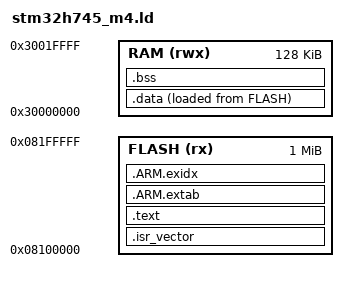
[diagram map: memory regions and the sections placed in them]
ENTRY(Reset_Handler)

MEMORY
{
    FLASH (rx) : ORIGIN = 0x08100000, LENGTH = 1024K
    RAM   (rwx): ORIGIN = 0x30000000, LENGTH = 128K
}

_estack = ORIGIN(RAM) + LENGTH(RAM);

SECTIONS
{
    .isr_vector :
    {
        KEEP(*(.isr_vector))
    } > FLASH

    .text :
    {
        *(.text*)
        *(.rodata*)
        . = ALIGN(4);
    } > FLASH

    .ARM.extab :
    {
        *(.ARM.extab* .gnu.linkonce.armextab.*)
    } > FLASH

    .ARM.exidx :
    {
        __exidx_start = .;
        *(.ARM.exidx* .gnu.linkonce.armexidx.*)
        __exidx_end = .;
    } > FLASH

    .data : ALIGN(4)
    {
        _sdata = .;
        *(.data*)
        . = ALIGN(4);
        _edata = .;
    } > RAM AT > FLASH

    _sidata = LOADADDR(.data);

    .bss (NOLOAD) : ALIGN(4)
    {
        _sbss = .;
        *(.bss*)
        *(COMMON)
        . = ALIGN(4);
        _ebss = .;
    } > RAM
}
